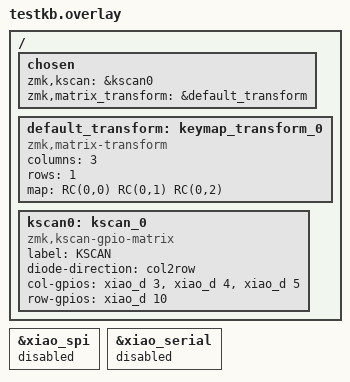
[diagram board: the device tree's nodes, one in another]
/*
 * Copyright (c) 2022 The ZMK Contributors
 *
 * SPDX-License-Identifier: MIT
 */

#include <dt-bindings/zmk/matrix_transform.h>

/ {
    chosen {
        zmk,kscan = &kscan0;
        zmk,matrix_transform = &default_transform;
    /delete-property/ zephyr,console;
    /delete-property/ zephyr,shell-uart;
    };

    default_transform: keymap_transform_0 {
        compatible = "zmk,matrix-transform";
        columns = <3>;
        rows = <1>;
        map = <
    RC(0,0) RC(0,1) RC(0,2)
        >;
    };


    kscan0: kscan_0 {
        compatible = "zmk,kscan-gpio-matrix";
        label = "KSCAN";
        diode-direction = "col2row";
        col-gpios
            = <&xiao_d 3 GPIO_ACTIVE_HIGH>
            , <&xiao_d 4 GPIO_ACTIVE_HIGH>
            , <&xiao_d 5 GPIO_ACTIVE_HIGH>
            ;
        row-gpios
            = <&xiao_d 10 (GPIO_ACTIVE_HIGH | GPIO_PULL_DOWN)>
            ;
    };

};

&xiao_spi { status = "disabled"; };
&xiao_serial { status = "disabled"; };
